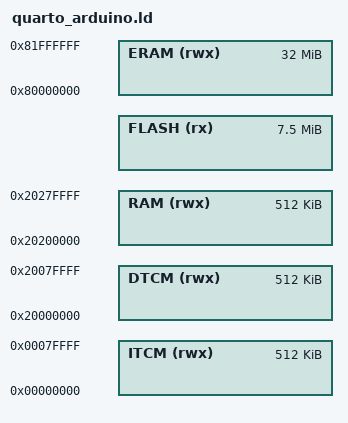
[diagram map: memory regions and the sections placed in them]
MEMORY
{
	ITCM (rwx) : ORIGIN = 0x0, LENGTH = 512k
	DTCM (rwx) : ORIGIN = 0x20000000, LENGTH = 512k
	RAM (rwx) : ORIGIN = 0x20200000, LENGTH = 512k
	FLASH (rx) : ORIGIN = DEFINED(BOOT_FROM_APP)? 0x60080000 : 0x60040000 , LENGTH = 0x780000
	ERAM (rwx) : ORIGIN = 0x80000000, LENGTH = 32M
}

ENTRY(ResetHandler)

INCLUDE "quarto_common.ld"
